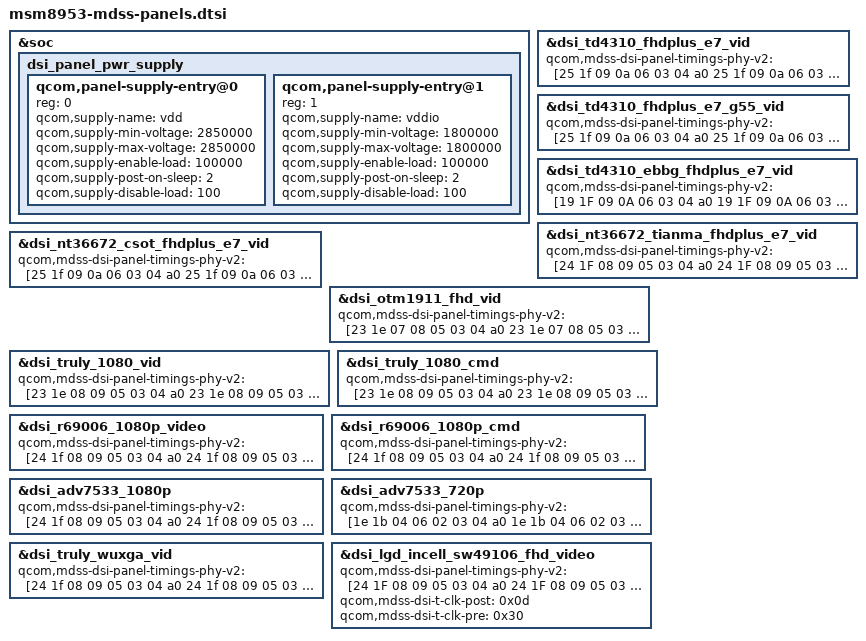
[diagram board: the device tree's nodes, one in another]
/* Copyright (c) 2015-2017, The Linux Foundation. All rights reserved.
 * Copyright (C) 2018 XiaoMi, Inc.
 *
 * This program is free software; you can redistribute it and/or modify
 * it under the terms of the GNU General Public License version 2 and
 * only version 2 as published by the Free Software Foundation.
 *
 * This program is distributed in the hope that it will be useful,
 * but WITHOUT ANY WARRANTY; without even the implied warranty of
 * MERCHANTABILITY or FITNESS FOR A PARTICULAR PURPOSE.  See the
 * GNU General Public License for more details.
 */

#include "dsi-panel-sim-video.dtsi"
#include "dsi-panel-sim-dualmipi-video.dtsi"
#include "dsi-panel-sim-cmd.dtsi"
#include "dsi-panel-sim-dualmipi-cmd.dtsi"
#include "dsi-panel-truly-1080p-video.dtsi"
#include "dsi-panel-truly-1080p-cmd.dtsi"
#include "dsi-adv7533-1080p.dtsi"
#include "dsi-adv7533-720p.dtsi"
#include "dsi-panel-r69006-1080p-video.dtsi"
#include "dsi-panel-r69006-1080p-cmd.dtsi"
#include "dsi-panel-truly-wuxga-video.dtsi"
#include "dsi-panel-lt8912-480p-video.dtsi"
#include "dsi-panel-lt8912-1080p-video.dtsi"
#include "dsi-panel-lgd-incell-sw49106-fhd-video.dtsi"
#include "dsi-panel-otm1911-fhd-video.dtsi"
#include "dsi-panel-otm1911-fhdplus-video.dtsi"
#include "dsi-panel-ili7807-fhdplus-video.dtsi"
#include "dsi-panel-hx8399c-fhdplus-video.dtsi"
/*add begin for E7 display*/
#include "dsi-panel-td4310-fhdplus-video_e7.dtsi"
#include "dsi-panel-td4310-fhdplus-video_e7_g55.dtsi"
#include "dsi-panel-td4310-ebbg-fhdplus-video_e7.dtsi"
#include "dsi-panel-nt36672-tianma-fhdplus-video_e7.dtsi"
#include "dsi-panel-nt36672-csot-fhdplus-video_e7.dtsi"
/*add end for E7 display*/
&soc {
	dsi_panel_pwr_supply: dsi_panel_pwr_supply {
		#address-cells = <1>;
		#size-cells = <0>;

		qcom,panel-supply-entry@0 {
			reg = <0>;
			qcom,supply-name = "vdd";
			qcom,supply-min-voltage = <2850000>;
			qcom,supply-max-voltage = <2850000>;
			qcom,supply-enable-load = <100000>;
			qcom,supply-post-on-sleep= <2>;
			qcom,supply-disable-load = <100>;
		};

		qcom,panel-supply-entry@1 {
			reg = <1>;
			qcom,supply-name = "vddio";
			qcom,supply-min-voltage = <1800000>;
			qcom,supply-max-voltage = <1800000>;
			qcom,supply-enable-load = <100000>;
			qcom,supply-post-on-sleep= <2>;
			qcom,supply-disable-load = <100>;
		};
	};
};

/*add begin for E7 display*/
&dsi_td4310_fhdplus_e7_vid {
	qcom,mdss-dsi-panel-timings-phy-v2 = [25 1f 09 0a 06 03 04 a0
					      25 1f 09 0a 06 03 04 a0
					      25 1f 09 0a 06 03 04 a0
					      25 1f 09 0a 06 03 04 a0
					      25 1f 08 0a 06 03 04 a0];
};

&dsi_td4310_fhdplus_e7_g55_vid {
	qcom,mdss-dsi-panel-timings-phy-v2 = [25 1f 09 0a 06 03 04 a0
					      25 1f 09 0a 06 03 04 a0
					      25 1f 09 0a 06 03 04 a0
					      25 1f 09 0a 06 03 04 a0
					      25 1f 08 0a 06 03 04 a0];
};

&dsi_td4310_ebbg_fhdplus_e7_vid {
	qcom,mdss-dsi-panel-timings-phy-v2 = [19 1F 09 0A 06 03 04 a0
		19 1F 09 0A 06 03 04 a0
		19 1F 09 0A 06 03 04 a0
		19 1F 09 0A 06 03 04 a0
		19 1E 08 0A 06 03 04 a0];
};

&dsi_nt36672_tianma_fhdplus_e7_vid {
	qcom,mdss-dsi-panel-timings-phy-v2 = [24 1F 08 09 05 03 04 a0
		24 1F 08 09 05 03 04 a0
		24 1F 08 09 05 03 04 a0
		24 1F 08 09 05 03 04 a0
		24 1C 08 09 05 03 04 a0];
};

&dsi_nt36672_csot_fhdplus_e7_vid {
	qcom,mdss-dsi-panel-timings-phy-v2 = [25 1f 09 0a 06 03 04 a0
		25 1f 09 0a 06 03 04 a0
		25 1f 09 0a 06 03 04 a0
		25 1f 09 0a 06 03 04 a0
		25 1e 08 0a 06 03 04 a0];
};
/*add end for E7 display*/

&dsi_otm1911_fhd_vid {
	qcom,mdss-dsi-panel-timings-phy-v2 = [23 1e 07 08 05 03 04 a0
		23 1e 07 08 05 03 04 a0
		23 1e 07 08 05 03 04 a0
		23 1e 07 08 05 03 04 a0
		23 18 07 08 05 03 04 a0];
};

&dsi_truly_1080_vid {
	qcom,mdss-dsi-panel-timings-phy-v2 = [23 1e 08 09 05 03 04 a0
		23 1e 08 09 05 03 04 a0
		23 1e 08 09 05 03 04 a0
		23 1e 08 09 05 03 04 a0
		23 1a 08 09 05 03 04 a0];
};

&dsi_truly_1080_cmd {
	qcom,mdss-dsi-panel-timings-phy-v2 = [23 1e 08 09 05 03 04 a0
		23 1e 08 09 05 03 04 a0
		23 1e 08 09 05 03 04 a0
		23 1e 08 09 05 03 04 a0
		23 1a 08 09 05 03 04 a0];
};

&dsi_r69006_1080p_video {
	qcom,mdss-dsi-panel-timings-phy-v2 = [24 1f 08 09 05 03 04 a0
		24 1f 08 09 05 03 04 a0
		24 1f 08 09 05 03 04 a0
		24 1f 08 09 05 03 04 a0
		24 1b 08 09 05 03 04 a0];
};

&dsi_r69006_1080p_cmd{
	qcom,mdss-dsi-panel-timings-phy-v2 = [24 1f 08 09 05 03 04 a0
		24 1f 08 09 05 03 04 a0
		24 1f 08 09 05 03 04 a0
		24 1f 08 09 05 03 04 a0
		24 1b 08 09 05 03 04 a0];
};

&dsi_adv7533_1080p {
	qcom,mdss-dsi-panel-timings-phy-v2 = [24 1f 08 09 05 03 04 a0
		24 1f 08 09 05 03 04 a0
		24 1f 08 09 05 03 04 a0
		24 1f 08 09 05 03 04 a0
		24 1b 08 09 05 03 04 a0];
};

&dsi_adv7533_720p {
	qcom,mdss-dsi-panel-timings-phy-v2 = [1e 1b 04 06 02 03 04 a0
		1e 1b 04 06 02 03 04 a0
		1e 1b 04 06 02 03 04 a0
		1e 1b 04 06 02 03 04 a0
		1e 0e 04 05 02 03 04 a0];
};

&dsi_truly_wuxga_vid {
	qcom,mdss-dsi-panel-timings-phy-v2 = [24 1f 08 09 05 03 04 a0
		24 1f 08 09 05 03 04 a0
		24 1f 08 09 05 03 04 a0
		24 1f 08 09 05 03 04 a0
		24 1c 08 09 05 03 04 a0];
};

&dsi_lgd_incell_sw49106_fhd_video {
	qcom,mdss-dsi-panel-timings-phy-v2 = [24 1F 08 09 05 03 04 a0
		24 1F 08 09 05 03 04 a0
		24 1F 08 09 05 03 04 a0
		24 1F 08 09 05 03 04 a0
		24 1B 08 09 05 03 04 a0];
		qcom,mdss-dsi-t-clk-post = <0x0d>;
		qcom,mdss-dsi-t-clk-pre = <0x30>;
};
